# HDSC_HC32M120J6TB register map
Vendor: HDSC Co.,Ltd.; Series: ARMCM0P; File version: 1.0
CPU: CM0P r0p1, little endian, no MPU, no FPU, 4 interrupt priority bits
Registers are 32-bit, read-write, reset 0x0 unless marked. A register's access mark holds for its fields unless they carry their own. Offsets are from the block's base; lines under a group give offsets from that group; [hi:lo] are bit positions; {n}, {i} and the like mark numbered series; 'fields as' and 'values as' point back to an identical list; <NAME> marks a mode.

## Memory map
0x000000C0 ICG size 0x20
0x40000000 CTC size 0xC
0x40000800 EFM size 0x285
0x40000C00 AOS size 0x88
0x40001800 USART1 size 0x10 — desc USART
0x40001C00 USART2 size 0x10 — desc USART
0x40002000 USART3 size 0x10 — desc USART
0x40003800 SPI size 0x1C
0x40004800 I2C size 0x34
0x40005800 TMR0 size 0x18
0x40006000 TMR2 size 0x24
0x40006800 TMR4 size 0x41C
0x40006C00 EMB size 0x18
0x40007000 TMRA size 0x148
0x40007800 TMRB1 size 0x144 — desc TMRB
0x40007C00 TMRB2 size 0x144 — desc TMRB
0x40008000 TMRB3 size 0x144 — desc TMRB
0x40008400 TMRB4 size 0x144 — desc TMRB
0x4000B800 ADC size 0xCE
0x4000C800 CMP1 size 0x6 — desc CMP
0x4000C810 CMP2 size 0x6 — desc CMP
0x4000CC00 SWDT size 0xC
0x40011000 INTC size 0x100
0x40013000 DMA size 0x90
0x40013800 PORT size 0x5F
0x40014000 PWC size 0x41
0x40014100 RMU size 0x2
0x40014400 CMU size 0x3D
0x40015000 DBGC size 0x8
0x40015400 CRC size 0x100
0xE0042000 DBGC_T size 0x1C

## ADC
Base 0x4000B800
0x00 STR 8-bit
  [0] STRT
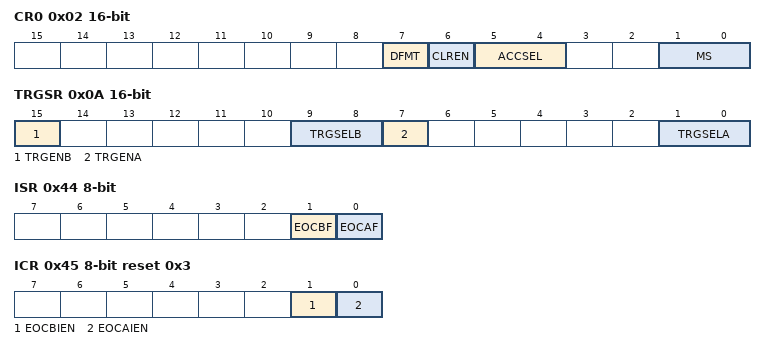
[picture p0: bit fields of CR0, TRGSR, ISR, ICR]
0x02 CR0 16-bit
  [7] DFMT, [6] CLREN, [5:4] ACCSEL, [1:0] MS
0x04 CR1 16-bit
  [2] RSCHSEL
0x0A TRGSR 16-bit
  [15] TRGENB, [9:8] TRGSELB, [7] TRGENA, [1:0] TRGSELA
0x0C CHSELRA0 16-bit
  [11:0] CHSELA
0x10 CHSELRB0 16-bit
  [11:0] CHSELB
0x18 EXCHSELR 8-bit
  [0] EXCHSEL
0x20 SSTR 8-bit reset 0xB
0x44 ISR 8-bit ro
  [1] EOCBF, [0] EOCAF
0x45 ICR 8-bit reset 0x3
  [1] EOCBIEN, [0] EOCAIEN
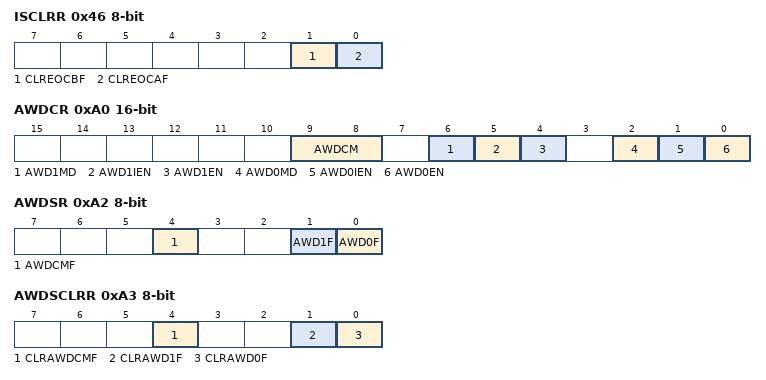
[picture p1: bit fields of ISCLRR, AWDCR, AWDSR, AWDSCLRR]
0x46 ISCLRR 8-bit wo
  [1] CLREOCBF, [0] CLREOCAF
{0x50+2i} DR{i} 16-bit ro (i=0..11)
0xA0 AWDCR 16-bit
  [9:8] AWDCM, [6] AWD1MD, [5] AWD1IEN, [4] AWD1EN, [2] AWD0MD, [1] AWD0IEN, [0] AWD0EN
0xA2 AWDSR 8-bit ro
  [4] AWDCMF, [1] AWD1F, [0] AWD0F
0xA3 AWDSCLRR 8-bit wo
  [4] CLRAWDCMF, [1] CLRAWD1F, [0] CLRAWD0F
0xA4 AWD0DR0 16-bit
0xA6 AWD0DR1 16-bit reset 0xFFFF
0xA8 AWD0CHSR 8-bit
  [4:0] AWDCH
0xAC AWD1DR0 16-bit
0xAE AWD1DR1 16-bit reset 0xFFFF
0xB0 AWD1CHSR 8-bit
  [4:0] AWDCH
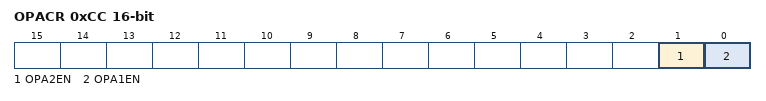
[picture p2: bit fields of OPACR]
0xCC OPACR 16-bit
  [1] OPA2EN, [0] OPA1EN

## AOS
Base 0x40000C00
0x00 INTC_STRGCR wo
  [0] STRG
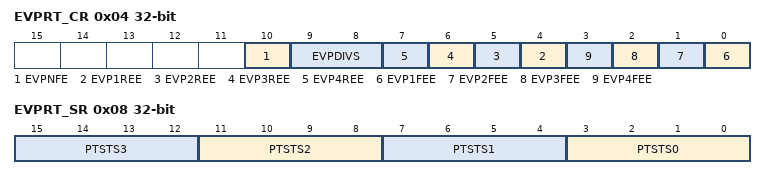
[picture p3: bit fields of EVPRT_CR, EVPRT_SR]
0x04 EVPRT_CR
  [10] EVPNFE, [9:8] EVPDIVS, [n+3] EVP{n}REE (n=1..4), [n-1] EVP{n}FEE (n=1..4)
0x08 EVPRT_SR ro
  [4n+3:4n] PTSTS{n} (n=0..3)
0x20 TMR0_HTSSR reset 0x7F
  [6:0] TRGSEL
0x20 TMR2_HTSSR reset 0x7F
  [6:0] TRGSEL
0x40 TMRA_HTSSR reset 0x7F
  [6:0] TRGSEL
0x50 TMRB_HTSSR reset 0x7F
  [6:0] TRGSEL
0x60 ADC_ITRGSELR0 reset 0x7F
  [6:0] TRGSEL
0x64 ADC_ITRGSELR1 reset 0x7F
  [6:0] TRGSEL
0x80 DMA0_TRGSEL reset 0x7F
  [6:0] TRGSEL
0x84 DMA1_TRGSEL reset 0x7F
  [6:0] TRGSEL

## CMP1 — desc CMP
Base 0x4000C800
Same registers: CMP2 0x4000C810
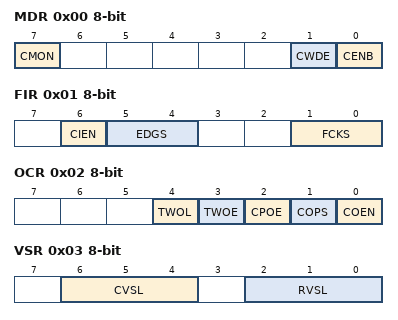
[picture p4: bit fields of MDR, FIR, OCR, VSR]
0x00 MDR 8-bit
  [7] CMON ro, [1] CWDE, [0] CENB
0x01 FIR 8-bit
  [6] CIEN, [5:4] EDGS, [1:0] FCKS
0x02 OCR 8-bit
  [4] TWOL, [3] TWOE, [2] CPOE, [1] COPS, [0] COEN
0x03 VSR 8-bit
  [6:4] CVSL, [2:0] RVSL
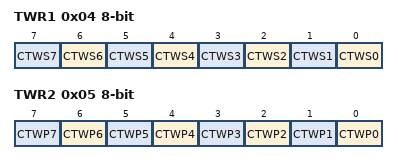
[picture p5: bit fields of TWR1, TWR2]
0x04 TWR1 8-bit
  [n] CTWS{n} (n=0..7)
0x05 TWR2 8-bit
  [n] CTWP{n} (n=0..7)

## CMU
Base 0x40014400
0x00 PERICKSEL 8-bit
  [2:0] PERICKSEL
0x04 XTALSTDSR 8-bit
  [0] XTALSTDF
0x08 SCKDIVR 8-bit
  [2:0] SCKDIV
0x0C CKSWR 8-bit
  [1:0] CKSW
0x10 XTALCR 8-bit reset 0x1
  [0] XTALSTP
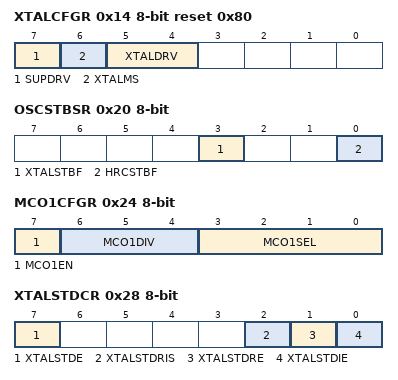
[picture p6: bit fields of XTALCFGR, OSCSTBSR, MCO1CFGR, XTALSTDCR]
0x14 XTALCFGR 8-bit reset 0x80
  [7] SUPDRV, [6] XTALMS, [5:4] XTALDRV
0x15 XTALSTBCR 8-bit
  [2:0] XTALSTB
0x18 HRCCR 8-bit
  [0] HRCSTP
0x20 OSCSTBSR 8-bit ro
  [3] XTALSTBF, [0] HRCSTBF
0x24 MCO1CFGR 8-bit
  [7] MCO1EN, [6:4] MCO1DIV, [3:0] MCO1SEL
0x28 XTALSTDCR 8-bit
  [7] XTALSTDE, [2] XTALSTDRIS, [1] XTALSTDRE, [0] XTALSTDIE
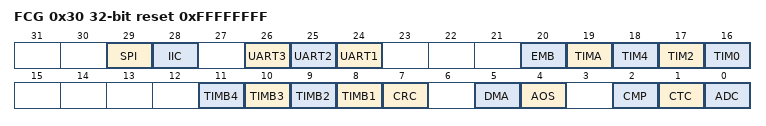
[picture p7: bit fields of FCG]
0x30 FCG reset 0xFFFFFFFF
  [29] SPI, [28] IIC, [26] UART3, [25] UART2, [24] UART1, [20] EMB, [19] TIMA, [18] TIM4, [17] TIM2, [16] TIM0, [n+7] TIMB{n} (n=1..4), [7] CRC, [5] DMA, [4] AOS, [2] CMP, [1] CTC, [0] ADC
0x3C LRCCR 8-bit
  [0] LRCSTP
